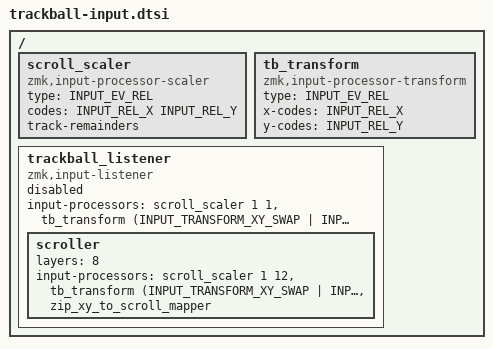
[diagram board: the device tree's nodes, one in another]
/* Shared pointer processing, applied once on the host-facing central. */
#include <zephyr/dt-bindings/input/input-event-codes.h>
#include <dt-bindings/zmk/input_transform.h>
#include <input/processors.dtsi>

/ {
    scroll_scaler: scroll_scaler {
        compatible = "zmk,input-processor-scaler";
        #input-processor-cells = <2>;
        type = <INPUT_EV_REL>;
        codes = <INPUT_REL_X INPUT_REL_Y>;
        track-remainders;
    };

    tb_transform: tb_transform {
        compatible = "zmk,input-processor-transform";
        #input-processor-cells = <1>;
        type = <INPUT_EV_REL>;
        x-codes = <INPUT_REL_X>;
        y-codes = <INPUT_REL_Y>;
    };

    trackball_listener: trackball_listener {
        compatible = "zmk,input-listener";
        status = "disabled";
        input-processors = <&scroll_scaler 1 1 &tb_transform (INPUT_TRANSFORM_XY_SWAP | INPUT_TRANSFORM_X_INVERT)>;

        scroller {
            layers = <8>;
            /* Preserve nominal scroll speed: 600 / 12 equals 800 / 16. */
            input-processors = <&scroll_scaler 1 12 &tb_transform (INPUT_TRANSFORM_XY_SWAP | INPUT_TRANSFORM_X_INVERT | INPUT_TRANSFORM_Y_INVERT) &zip_xy_to_scroll_mapper>;
        };
    };
};
